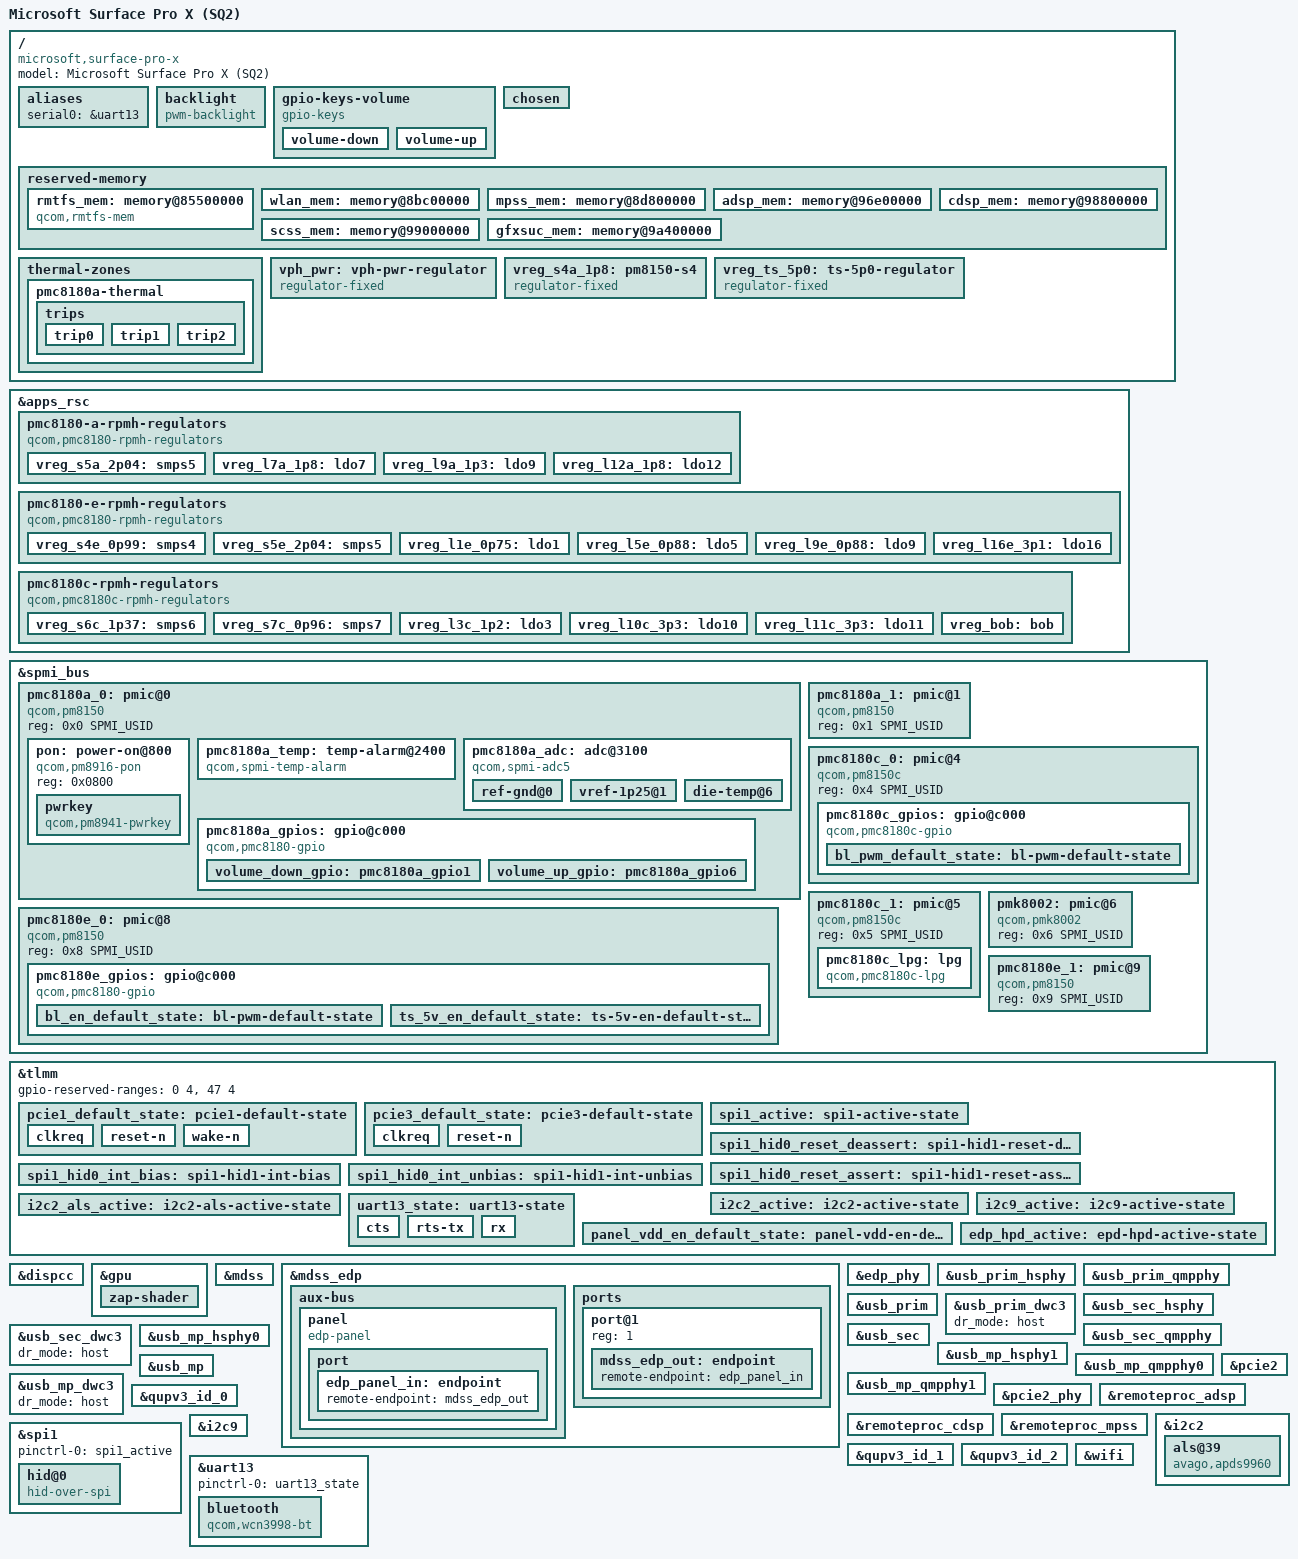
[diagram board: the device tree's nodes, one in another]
// SPDX-License-Identifier: BSD-3-Clause
/*
 * Based on:
 % - sc8180x-primus.dts
 % - sc8180x-lenovo-flex-5g.dts
 */

/dts-v1/;

#include <dt-bindings/gpio/gpio.h>
#include <dt-bindings/input/linux-event-codes.h>
#include <dt-bindings/interrupt-controller/irq.h>
#include <dt-bindings/regulator/qcom,rpmh-regulator.h>
#include <dt-bindings/spmi/spmi.h>
#include <dt-bindings/iio/qcom,spmi-vadc.h>
#include "sc8180x.dtsi"


/ {
	model = "Microsoft Surface Pro X (SQ2)";
	compatible = "microsoft,surface-pro-x", "qcom,sc8180x";

	aliases {
		serial0 = &uart13;
	};

	backlight: backlight {
		compatible = "pwm-backlight";

		pwms = <&pmc8180c_lpg 4 5000000>;
		enable-gpios = <&pmc8180e_gpios 1 GPIO_ACTIVE_HIGH>;

		pinctrl-names = "default";
		pinctrl-0 = <&bl_pwm_default_state &bl_en_default_state>;
	};

	gpio-keys-volume {
		compatible = "gpio-keys";
		label = "Volume Buttons";
		autorepeat;

		pinctrl-names = "default";
		pinctrl-0 = <&volume_down_gpio &volume_up_gpio>;

		volume-down {
			label = "Volume Down";
			gpios = <&pmc8180a_gpios 1 GPIO_ACTIVE_LOW>;
			linux,code = <KEY_VOLUMEDOWN>;
		};

		volume-up {
			label = "Volume Up";
			gpios = <&pmc8180a_gpios 6 GPIO_ACTIVE_LOW>;
			linux,code = <KEY_VOLUMEUP>;
		};
	};

	chosen {
	};

	reserved-memory {
		// Sources for memory regions:
		// - Windows Device Manager/ACPI
		// - Windows Registry/driver .inf files

		// Windows Registry entries:
		//
		// - ADSP:
		//   - alignment:     0x100000
		//   - reservation:  0x1a00000
		//
		// - CDSP:
		//   - alignment:     0x100000
		//   - reservation:   0x800000
		//
		// - GFXSUC:
		//   - alignment:       0x1000
		//   - reservation:     0x5000
		//
		// - MPSS/MODEM:
		//   - address:     0x8d800000
		//   - alignment:     0x400000
		//   - reservation:  0x9600000
		//
		// - SCSS/SLPI:
		//   - alignment:     0x100000
		//   - reservation:  0x1400000
		//
		// - IPA (no firmware?):
		//   - alignment:     0x100000
		//   - reservation:   0x100000
		//
		// - SPSS (no firmware?):
		//   - alignment:     0x100000
		//   - reservation:   0x100000
		//
		// - MBA (bogus?):
		//   - alignment:     0x100000
		//
		// - VENUS (bogus?):
		//   - alignment:          0x0
		//   - reservation:   0x500000
		//
		// - WCNSS (bogus?):
		//   - alignment:     0x100000
		//   - reservation:        0x0

		// Windows Device Manager memory map:
		//
		// [...]
		// 0x85d00000 ++  0x200000	RMTFS
		// 0x85f00000 ++ 0x5d00000	<free>
		// 0x8b700000 ++  0x500000	CAMERA
		// 0x8bc00000 ++  0x180000	WLAN
		// 0x8bd80000 ++ 0xe780000	<free for image loader>
		// 0x9a500000 ++  0x600000	QSM
		// [...]

		// Resulting memory map:
		//
		// [...]
		// 0x85500000 ++  0x200000	RMTFS
		// 0x85700000
		// 0x85f00000 ++ 0x5d00000	<reserved>
		// 0x8b700000 ++  0x500000	CAMERA
		// 0x8bc00000 ++  0x180000	WLAN
		// 0x8bd80000 ++ 0x1a80000	<free>
		// 0x8d800000 ++ 0x9600000	MPSS
		// 0x96e00000 ++ 0x1a00000	ADSP
		// 0x98800000 ++  0x800000	CDSP
		// 0x99000000 ++ 0x1400000	SCSS
		// 0x9a400000 ++    0x5000	GFXSUC
		// 0x9a405000 ++   0xfb000	<free>
		// 0x9a500000 ++  0x600000	QSM
		// [...]

		// Notes:
		// - RMTFS doesn't work at 0x85d00000, but does work at
		//   0x85500000 (same as Lenovo Flex 5G).
		// - An 8MB region for CDSP seems a bit small. Similarly, the
		//   MPSS region seems to be a bit large... do we need to resize
		//   things?

		rmtfs_mem: memory@85500000 {
			compatible = "qcom,rmtfs-mem";
			reg = <0x0 0x85500000 0x0 0x200000>;
			no-map;

			qcom,client-id = <1>;
			qcom,vmid = <15>;
		};

		wlan_mem: memory@8bc00000 {
			reg = <0x0 0x8bc00000 0x0 0x180000>;
			no-map;
		};

		mpss_mem: memory@8d800000 {
			reg = <0x0 0x8d800000 0x0 0x9600000>;
			no-map;
		};

		adsp_mem: memory@96e00000 {
			reg = <0x0 0x96e00000 0x0 0x1a00000>;
			no-map;
		};

		cdsp_mem: memory@98800000 {
			reg = <0x0 0x98800000 0x0 0x800000>;
			no-map;
		};

		scss_mem: memory@99000000 {
			reg = <0x0 0x99000000 0x0 0x1400000>;
			no-map;
		};

		gfxsuc_mem: memory@9a400000 {
			reg = <0x0 0x9a400000 0x0 0x5000>;
			no-map;
		};
	};

	thermal-zones {
		pmc8180a-thermal {
			polling-delay-passive = <100>;
			polling-delay = <0>;

			thermal-sensors = <&pmc8180a_temp>;

			trips {
				trip0 {
					temperature = <95000>;
					hysteresis = <0>;
					type = "passive";
				};

				trip1 {
					temperature = <115000>;
					hysteresis = <0>;
					type = "hot";
				};

				trip2 {
					temperature = <145000>;
					hysteresis = <0>;
					type = "critical";
				};
			};
		};
	};

	vph_pwr: vph-pwr-regulator {
		compatible = "regulator-fixed";
		regulator-name = "vph_pwr";
		regulator-min-microvolt = <3300000>;	// TODO: measure this (see pm660.dtsi/vadc_vph_pwr)
		regulator-max-microvolt = <3300000>;
	};

	vreg_s4a_1p8: pm8150-s4 {
		compatible = "regulator-fixed";
		regulator-name = "vreg_s4a_1p8";

		regulator-min-microvolt = <1800000>;
		regulator-max-microvolt = <1800000>;

		regulator-always-on;
		regulator-boot-on;

		vin-supply = <&vph_pwr>;
	};

	vreg_ts_5p0: ts-5p0-regulator {
		compatible = "regulator-fixed";
		regulator-name = "vreg_ts_5p0";

		regulator-min-microvolt = <5000000>;
		regulator-max-microvolt = <5000000>;

		gpio = <&pmc8180e_gpios 10 GPIO_ACTIVE_HIGH>;
		enable-active-high;

		pinctrl-names = "default";
		pinctrl-0 = <&ts_5v_en_default_state>;
	};
};


&apps_rsc {
	pmc8180-a-rpmh-regulators {
		compatible = "qcom,pmc8180-rpmh-regulators";
		qcom,pmic-id = "a";

		vdd-s1-supply = <&vph_pwr>;
		vdd-s2-supply = <&vph_pwr>;
		vdd-s3-supply = <&vph_pwr>;
		vdd-s4-supply = <&vph_pwr>;
		vdd-s5-supply = <&vph_pwr>;
		vdd-s6-supply = <&vph_pwr>;
		vdd-s7-supply = <&vph_pwr>;
		vdd-s8-supply = <&vph_pwr>;
		vdd-s9-supply = <&vph_pwr>;
		vdd-s10-supply = <&vph_pwr>;

		vdd-l1-l8-l11-supply = <&vreg_s6c_1p37>;
		vdd-l2-l10-supply = <&vreg_bob>;
		vdd-l3-l4-l5-l18-supply = <&vreg_s7c_0p96>;
		vdd-l6-l9-supply = <&vreg_s6c_1p37>;
		vdd-l7-l12-l14-l15-supply = <&vreg_s5a_2p04>;
		vdd-l13-l16-l17-supply = <&vreg_bob>;

		vreg_s5a_2p04: smps5 {
			regulator-min-microvolt = <2040000>;
			regulator-max-microvolt = <2040000>;
		};

		vreg_l7a_1p8: ldo7 {
			regulator-min-microvolt = <1800000>;
			regulator-max-microvolt = <1800000>;
			regulator-initial-mode = <RPMH_REGULATOR_MODE_HPM>;
		};

		vreg_l9a_1p3: ldo9 {
			regulator-min-microvolt = <1296000>;
			regulator-max-microvolt = <1304000>;
			regulator-initial-mode = <RPMH_REGULATOR_MODE_HPM>;
		};

		vreg_l12a_1p8: ldo12 {
			regulator-min-microvolt = <1800000>;
			regulator-max-microvolt = <1800000>;
			regulator-initial-mode = <RPMH_REGULATOR_MODE_HPM>;
		};
	};

	pmc8180-e-rpmh-regulators {
		compatible = "qcom,pmc8180-rpmh-regulators";
		qcom,pmic-id = "e";

		vdd-s1-supply = <&vph_pwr>;
		vdd-s2-supply = <&vph_pwr>;
		vdd-s3-supply = <&vph_pwr>;
		vdd-s4-supply = <&vph_pwr>;
		vdd-s5-supply = <&vph_pwr>;
		vdd-s6-supply = <&vph_pwr>;
		vdd-s7-supply = <&vph_pwr>;
		vdd-s8-supply = <&vph_pwr>;
		vdd-s9-supply = <&vph_pwr>;
		vdd-s10-supply = <&vph_pwr>;

		vdd-l1-l8-l11-supply = <&vreg_s4e_0p99>;
		vdd-l2-l10-supply = <&vreg_bob>;
		vdd-l3-l4-l5-l18-supply = <&vreg_s4e_0p99>;
		vdd-l6-l9-supply = <&vreg_s4e_0p99>;
		vdd-l7-l12-l14-l15-supply = <&vreg_s5e_2p04>;
		vdd-l13-l16-l17-supply = <&vreg_bob>;

		vreg_s4e_0p99: smps4 {
			regulator-min-microvolt = <992000>;
			regulator-max-microvolt = <992000>;
			regulator-initial-mode = <RPMH_REGULATOR_MODE_HPM>;
		};

		vreg_s5e_2p04: smps5 {
			regulator-min-microvolt = <2040000>;
			regulator-max-microvolt = <2040000>;
			regulator-initial-mode = <RPMH_REGULATOR_MODE_HPM>;
		};

		vreg_l1e_0p75: ldo1 {
			regulator-min-microvolt = <752000>;
			regulator-max-microvolt = <752000>;
			regulator-initial-mode = <RPMH_REGULATOR_MODE_HPM>;
		};

		vreg_l5e_0p88: ldo5 {
			regulator-min-microvolt = <880000>;
			regulator-max-microvolt = <880000>;
			regulator-initial-mode = <RPMH_REGULATOR_MODE_HPM>;
		};

		vreg_l9e_0p88: ldo9 {
			regulator-min-microvolt = <880000>;
			regulator-max-microvolt = <880000>;
			regulator-initial-mode = <RPMH_REGULATOR_MODE_HPM>;
		};

		vreg_l16e_3p1: ldo16 {
			regulator-min-microvolt = <3072000>;
			regulator-max-microvolt = <3072000>;
			regulator-initial-mode = <RPMH_REGULATOR_MODE_HPM>;
		};
	};

	pmc8180c-rpmh-regulators {
		compatible = "qcom,pmc8180c-rpmh-regulators";
		qcom,pmic-id = "c";

		vdd-s1-supply = <&vph_pwr>;
		vdd-s2-supply = <&vph_pwr>;
		vdd-s3-supply = <&vph_pwr>;
		vdd-s4-supply = <&vph_pwr>;
		vdd-s5-supply = <&vph_pwr>;
		vdd-s6-supply = <&vph_pwr>;
		vdd-s7-supply = <&vph_pwr>;
		vdd-s8-supply = <&vph_pwr>;

		vdd-l1-l8-supply = <&vreg_s4a_1p8>;
		vdd-l2-l3-supply = <&vreg_s6c_1p37>;
		vdd-l4-l5-l6-supply = <&vreg_bob>;
		vdd-l7-l11-supply = <&vreg_bob>;
		vdd-l9-l10-supply = <&vreg_bob>;

		vdd-bob-supply = <&vph_pwr>;
		vdd-flash-supply = <&vreg_bob>;
		vdd-rgb-supply = <&vreg_bob>;

		vreg_s6c_1p37: smps6 {
			regulator-min-microvolt = <1350000>;
			regulator-max-microvolt = <1372000>;
			regulator-initial-mode = <RPMH_REGULATOR_MODE_HPM>;
		};

		vreg_s7c_0p96: smps7 {
			regulator-min-microvolt = <960000>;
			regulator-max-microvolt = <960000>;
			regulator-initial-mode = <RPMH_REGULATOR_MODE_HPM>;
		};

		vreg_l3c_1p2: ldo3 {
			regulator-min-microvolt = <1200000>;
			regulator-max-microvolt = <1200000>;
			regulator-initial-mode = <RPMH_REGULATOR_MODE_HPM>;
		};

		vreg_l10c_3p3: ldo10 {
			regulator-min-microvolt = <3296000>;
			regulator-max-microvolt = <3312000>;
			regulator-initial-mode = <RPMH_REGULATOR_MODE_HPM>;
		};

		vreg_l11c_3p3: ldo11 {
			regulator-min-microvolt = <3296000>;
			regulator-max-microvolt = <3304000>;
			regulator-initial-mode = <RPMH_REGULATOR_MODE_HPM>;
		};

		vreg_bob: bob {
			regulator-min-microvolt = <3296000>;
			regulator-max-microvolt = <3350000>;
			regulator-initial-mode = <RPMH_REGULATOR_MODE_HPM>;
		};
	};
};


&spmi_bus {
	pmc8180a_0: pmic@0 {
		compatible = "qcom,pm8150", "qcom,spmi-pmic";
		reg = <0x0 SPMI_USID>;
		#address-cells = <1>;
		#size-cells = <0>;

		pon: power-on@800 {
			compatible = "qcom,pm8916-pon";
			reg = <0x0800>;

			pwrkey {
				compatible = "qcom,pm8941-pwrkey";
				interrupts = <0x0 0x8 0x0 IRQ_TYPE_EDGE_BOTH>;
				debounce = <15625>;
				bias-pull-up;
				linux,code = <KEY_POWER>;
			};
		};

		pmc8180a_temp: temp-alarm@2400 {
			compatible = "qcom,spmi-temp-alarm";
			reg = <0x2400>;
			interrupts = <0x0 0x24 0x0 IRQ_TYPE_EDGE_BOTH>;
			io-channels = <&pmc8180a_adc ADC5_DIE_TEMP>;
			io-channel-names = "thermal";
			#thermal-sensor-cells = <0>;
		};

		pmc8180a_adc: adc@3100 {
			compatible = "qcom,spmi-adc5";
			reg = <0x3100>;
			#address-cells = <1>;
			#size-cells = <0>;
			#io-channel-cells = <1>;
			interrupts = <0x0 0x31 0x0 IRQ_TYPE_EDGE_RISING>;

			ref-gnd@0 {
				reg = <ADC5_REF_GND>;
				qcom,pre-scaling = <1 1>;
				label = "ref_gnd";
			};

			vref-1p25@1 {
				reg = <ADC5_1P25VREF>;
				qcom,pre-scaling = <1 1>;
				label = "vref_1p25";
			};

			die-temp@6 {
				reg = <ADC5_DIE_TEMP>;
				qcom,pre-scaling = <1 1>;
				label = "die_temp";
			};
		};

		pmc8180a_gpios: gpio@c000 {
			compatible = "qcom,pmc8180-gpio";
			reg = <0xc000>;
			gpio-controller;
			#gpio-cells = <2>;
			interrupt-controller;
			#interrupt-cells = <2>;
		};
	};

	pmc8180a_1: pmic@1 {
		compatible = "qcom,pm8150", "qcom,spmi-pmic";
		reg = <0x1 SPMI_USID>;
		#address-cells = <1>;
		#size-cells = <0>;
	};

	pmc8180c_0: pmic@4 {
		compatible = "qcom,pm8150c", "qcom,spmi-pmic";
		reg = <0x4 SPMI_USID>;
		#address-cells = <1>;
		#size-cells = <0>;

		pmc8180c_gpios: gpio@c000 {
			compatible = "qcom,pmc8180c-gpio";
			reg = <0xc000>;
			gpio-controller;
			#gpio-cells = <2>;
			interrupt-controller;
			#interrupt-cells = <2>;
		};
	};

	pmc8180c_1: pmic@5 {
		compatible = "qcom,pm8150c", "qcom,spmi-pmic";
		reg = <0x5 SPMI_USID>;
		#address-cells = <1>;
		#size-cells = <0>;

		pmc8180c_lpg: lpg {
			compatible = "qcom,pmc8180c-lpg";
			#address-cells = <1>;
			#size-cells = <0>;
			#pwm-cells = <2>;
		};
	};

	pmk8002: pmic@6 {
		compatible = "qcom,pmk8002", "qcom,spmi-pmic";
		reg = <0x6 SPMI_USID>;
		#address-cells = <1>;
		#size-cells = <0>;
	};

	pmc8180e_0: pmic@8 {
		compatible = "qcom,pm8150", "qcom,spmi-pmic";
		reg = <0x8 SPMI_USID>;
		#address-cells = <1>;
		#size-cells = <0>;

		pmc8180e_gpios: gpio@c000 {
			compatible = "qcom,pmc8180-gpio";
			reg = <0xc000>;
			gpio-controller;
			#gpio-cells = <2>;
			interrupt-controller;
			#interrupt-cells = <2>;
		};
	};

	pmc8180e_1: pmic@9 {
		compatible = "qcom,pm8150", "qcom,spmi-pmic";
		reg = <0x9 SPMI_USID>;
		#address-cells = <1>;
		#size-cells = <0>;
	};
};


&tlmm {
	gpio-reserved-ranges = <0 4>, <47 4>;

	pcie1_default_state: pcie1-default-state {
		clkreq {
			pins = "gpio176";
			function = "pci_e2";
			bias-pull-up;
		};

		reset-n {
			pins = "gpio102";
			function = "gpio";

			drive-strength = <2>;
			output-low;
			bias-pull-down;
		};

		wake-n {
			pins = "gpio104";
			function = "gpio";

			drive-strength = <2>;
			bias-pull-up;
		};
	};

	pcie3_default_state: pcie3-default-state {
		clkreq {
			pins = "gpio178";
			function = "pci_e3";
			bias-pull-up;
		};

		reset-n {
			pins = "gpio179";
			function = "gpio";

			drive-strength = <2>;
			output-low;
			bias-pull-down;
		};
	};

	spi1_active: spi1-active-state {
		pins = "gpio114", "gpio115", "gpio116", "gpio117";
		function = "qup1";

		drive-strength = <6>;
		bias-disable;

		// Note: Drive strength and bias set based on qcom lahaina
		// (Surface Duo 2) DT.
	};

	spi1_hid0_reset_deassert: spi1-hid1-reset-deassert {
		pins = "gpio54";
		function = "gpio";

		drive-strength = <2>;
		bias-disable;
		output-high;
	};

	spi1_hid0_reset_assert: spi1-hid1-reset-assert {
		pins = "gpio54";
		function = "gpio";

		drive-strength = <2>;
		bias-disable;
		output-low;
	};

	spi1_hid0_int_bias: spi1-hid1-int-bias {
		pins = "gpio122";
		function = "gpio";

		input-enable;
		bias-pull-up;
	};

	spi1_hid0_int_unbias: spi1-hid1-int-unbias {
		pins = "gpio122";
		function = "gpio";

		input-enable;
		bias-disable;
	};

	i2c2_active: i2c2-active-state {
		pins = "gpio126", "gpio127";
		function = "qup2";

		bias-pull-up;
		drive-strength = <2>;
	};

	i2c2_als_active: i2c2-als-active-state {
		pins = "gpio24";
		function = "gpio";

		input-enable;
		bias-disable;
	};

	i2c9_active: i2c9-active-state {
		pins = "gpio39", "gpio40";
		function = "qup9";

		bias-pull-up;
		drive-strength = <2>;
	};

	uart13_state: uart13-state {
		cts {
			pins = "gpio43";
			function = "qup13";
			bias-pull-down;
		};

		rts-tx {
			pins = "gpio44", "gpio45";
			function = "qup13";
			drive-strength = <2>;
			bias-disable;
		};

		rx {
			pins = "gpio46";
			function = "qup13";
			bias-pull-up;
		};
	};

	panel_vdd_en_default_state: panel-vdd-en-default-state {
		pins = "gpio130";
		function = "gpio";

		drive-strength = <2>;
		bias-disable;
		output-high;
	};

	edp_hpd_active: epd-hpd-active-state {
		pins = "gpio10";
		function = "edp_hot";
	};
};

&pmc8180a_gpios {
	volume_down_gpio: pmc8180a_gpio1 {
		pins = "gpio1";
		function = "normal";
		input-enable;
		bias-pull-up;
		qcom,drive-strength = <0>;
	};

	volume_up_gpio: pmc8180a_gpio6 {
		pins = "gpio6";
		function = "normal";
		input-enable;
		bias-pull-up;
		qcom,drive-strength = <0>;
	};
};

&pmc8180c_gpios {
	bl_pwm_default_state: bl-pwm-default-state {
		pins = "gpio10";
		function = "func1";
	};
};

&pmc8180e_gpios {
	bl_en_default_state: bl-pwm-default-state {
		pins = "gpio1";
		function = "normal";
	};

	ts_5v_en_default_state: ts-5v-en-default-state {
		pins = "gpio10";
		function = "normal";
	};
};


&dispcc {
	status = "okay";
};

&gpu {
	status = "okay";

	zap-shader {
		memory-region = <&gfxsuc_mem>;
		firmware-name = "qcom/msft/surface/pro-x-sq2/qcdxkmsuc8180.mbn";
	};
};

&mdss {
	status = "okay";
};

&mdss_edp {
	data-lanes = <0 1 2 3>;

	pinctrl-0 = <&edp_hpd_active>;
	pinctrl-names = "default";

	status = "okay";

	aux-bus {
		panel {
			compatible = "edp-panel";
			no-hpd;

			enable-gpios = <&tlmm 130 GPIO_ACTIVE_HIGH>;

			pinctrl-names = "default";
			pinctrl-0 = <&panel_vdd_en_default_state>;

			backlight = <&backlight>;

			port {
				edp_panel_in: endpoint {
					remote-endpoint = <&mdss_edp_out>;
				};
			};
		};
	};

	ports {
		port@1 {
			reg = <1>;
			mdss_edp_out: endpoint {
				remote-endpoint = <&edp_panel_in>;
			};
		};
	};
};

&edp_phy {
	vdda-pll-supply = <&vreg_l5e_0p88>;
	vdda-phy-supply = <&vreg_l3c_1p2>;
};


&usb_prim_hsphy {
	status = "okay";
	vdda-pll-supply = <&vreg_l9e_0p88>;
	vdda18-supply = <&vreg_l12a_1p8>;
	vdda33-supply = <&vreg_l16e_3p1>;
};

&usb_prim_qmpphy {
	status = "okay";
	vdda-phy-supply = <&vreg_l3c_1p2>;
	vdda-pll-supply = <&vreg_l9e_0p88>;
};

&usb_prim {
	status = "okay";
};

&usb_prim_dwc3 {
	dr_mode = "host";
};

&usb_sec_hsphy {
	status = "okay";
	vdda-pll-supply = <&vreg_l9e_0p88>;
	vdda18-supply = <&vreg_l12a_1p8>;
	vdda33-supply = <&vreg_l16e_3p1>;
};

&usb_sec_qmpphy {
	status = "okay";
	vdda-phy-supply = <&vreg_l3c_1p2>;
	vdda-pll-supply = <&vreg_l9e_0p88>;
};

&usb_sec {
	status = "okay";
};

&usb_sec_dwc3 {
	dr_mode = "host";
};

&usb_mp_hsphy0 {
	status = "okay";
	vdda-pll-supply = <&vreg_l9e_0p88>;
	vdda18-supply = <&vreg_l12a_1p8>;
	vdda33-supply = <&vreg_l16e_3p1>;
};

&usb_mp_hsphy1 {
	status = "okay";
	vdda-pll-supply = <&vreg_l9e_0p88>;
	vdda18-supply = <&vreg_l12a_1p8>;
	vdda33-supply = <&vreg_l16e_3p1>;
};

&usb_mp_qmpphy0 {
	status = "okay";
	vdda-phy-supply = <&vreg_l3c_1p2>;
	vdda-pll-supply = <&vreg_l9e_0p88>;
};

&usb_mp_qmpphy1 {
	status = "okay";
	vdda-phy-supply = <&vreg_l3c_1p2>;
	vdda-pll-supply = <&vreg_l9e_0p88>;
};

&usb_mp {
	status = "okay";
};

&usb_mp_dwc3 {
	dr_mode = "host";
};


// TODO:
// - PCIe has some sleep mode via a dedicated GPIO for all devices/ports
// - PCIe 3 has pin connections, but hot-plug commands time out.
//   pcieport 0003:00:00.0: pciehp: Timeout on hotplug command 0x03c0 (issued 3030 msec ago)
// - PCIe 1 and 2 work together? How do we express this here?
//   - apparently 2 phys can work with one controller (each providing 2 lanes)
//   - support for this is WIP (by Johan Hovold)
//   - right now, there seem to be two options:
//     - rely on UEFI to configure the second phy for us, which may cause problems with suspend
//     - use 2 lanes only, which _hopefully_ lets us avoid the second phy for now

&pcie2 {
	status = "okay";

	num-lanes = <2>;

	perst-gpio = <&tlmm 102 GPIO_ACTIVE_LOW>;
	wake-gpio = <&tlmm 104 GPIO_ACTIVE_HIGH>;
	pinctrl-names = "default";
	pinctrl-0 = <&pcie1_default_state>;

	// phys = <&pcie1_lane>, <&pcie1_lane>;
	// phy-names = "pciephy0", "pciephy1";
};

// &pcie1_phy {
// 	status = "okay";
// 	vdda-phy-supply = <&vreg_l5e_0p88>;
// 	vdda-pll-supply = <&vreg_l3c_1p2>;
// };

&pcie2_phy {
	status = "okay";
	vdda-phy-supply = <&vreg_l5e_0p88>;
	vdda-pll-supply = <&vreg_l3c_1p2>;
};


&remoteproc_adsp {
	status = "okay";
	memory-region = <&adsp_mem>;
	firmware-name = "qcom/msft/surface/pro-x-sq2/qcadsp8180.mbn";
};

&remoteproc_cdsp {
	status = "okay";
	memory-region = <&cdsp_mem>;
	firmware-name = "qcom/msft/surface/pro-x-sq2/qccdsp8180.mbn";
};

&remoteproc_mpss {
	status = "okay";
	memory-region = <&mpss_mem>;
	firmware-name = "qcom/msft/surface/pro-x-sq2/qcmpss8180.mbn";
};


&qupv3_id_0 {
	status = "okay";
};

&spi1 {
	status = "okay";

	pinctrl-names = "default";
	pinctrl-0 = <&spi1_active>;

	hid@0 {
		compatible = "hid-over-spi";

		reg = <0>;
		// spi-max-frequency = <25000000>;
		spi-max-frequency = <12500000>;

		interrupts-extended = <&tlmm 122 IRQ_TYPE_EDGE_FALLING>;

		pinctrl-names = "active", "sleep", "reset";
		pinctrl-0 = <&spi1_hid0_reset_deassert &spi1_hid0_int_bias>;
		pinctrl-1 = <&spi1_hid0_reset_assert &spi1_hid0_int_unbias>;
		pinctrl-2 = <&spi1_hid0_reset_assert &spi1_hid0_int_bias>;

		vdd-supply = <&vreg_ts_5p0>;

		hid-descr-addr = <1>;
	};
};

&i2c2 {
	status = "okay";
	clock-frequency = <400000>;

	pinctrl-names = "default";
	pinctrl-0 = <&i2c2_active>, <&i2c2_als_active>;

	als@39 {
		// TODO: this should actually be a TCS3430
		compatible = "avago,apds9960";
		reg = <0x39>;

		interrupts-extended = <&tlmm 24 IRQ_TYPE_LEVEL_LOW>;
	};
};


&qupv3_id_1 {
	status = "okay";
};

&i2c9 {
	status = "okay";
	clock-frequency = <100000>;

	pinctrl-names = "default";
	pinctrl-0 = <&i2c9_active>;
};


&qupv3_id_2 {
	status = "okay";
};

&uart13 {
	status = "okay";

	pinctrl-names = "default";
	pinctrl-0 = <&uart13_state>;

	bluetooth {
		// Note: For some reason, the ROM version is given as 0x01
		//       whereas it should be 0x21. This prevents the firmware
		//       from being found, as these file names depend on the
		//       rom version. Symlinking
		//        - qca/crbtfw01.tlv to qca/crbtfw21.tlv
		//        - qca/crnv01.bin to qca/crnv21.bin
		//       fixes them. Windows is confirmed to use the 0x21
		//       files.

		compatible = "qcom,wcn3998-bt";

		vddio-supply = <&vreg_s4a_1p8>;
		vddxo-supply = <&vreg_l7a_1p8>;
		vddrf-supply = <&vreg_l9a_1p3>;
		vddch0-supply = <&vreg_l11c_3p3>;

		max-speed = <3200000>;
	};
};

&wifi {
	status = "okay";

	memory-region = <&wlan_mem>;

	vdd-0.8-cx-mx-supply = <&vreg_l1e_0p75>;
	vdd-1.8-xo-supply = <&vreg_l7a_1p8>;
	vdd-1.3-rfa-supply = <&vreg_l9a_1p3>;
	vdd-3.3-ch0-supply = <&vreg_l11c_3p3>;
	vdd-3.3-ch1-supply = <&vreg_l10c_3p3>;
};
